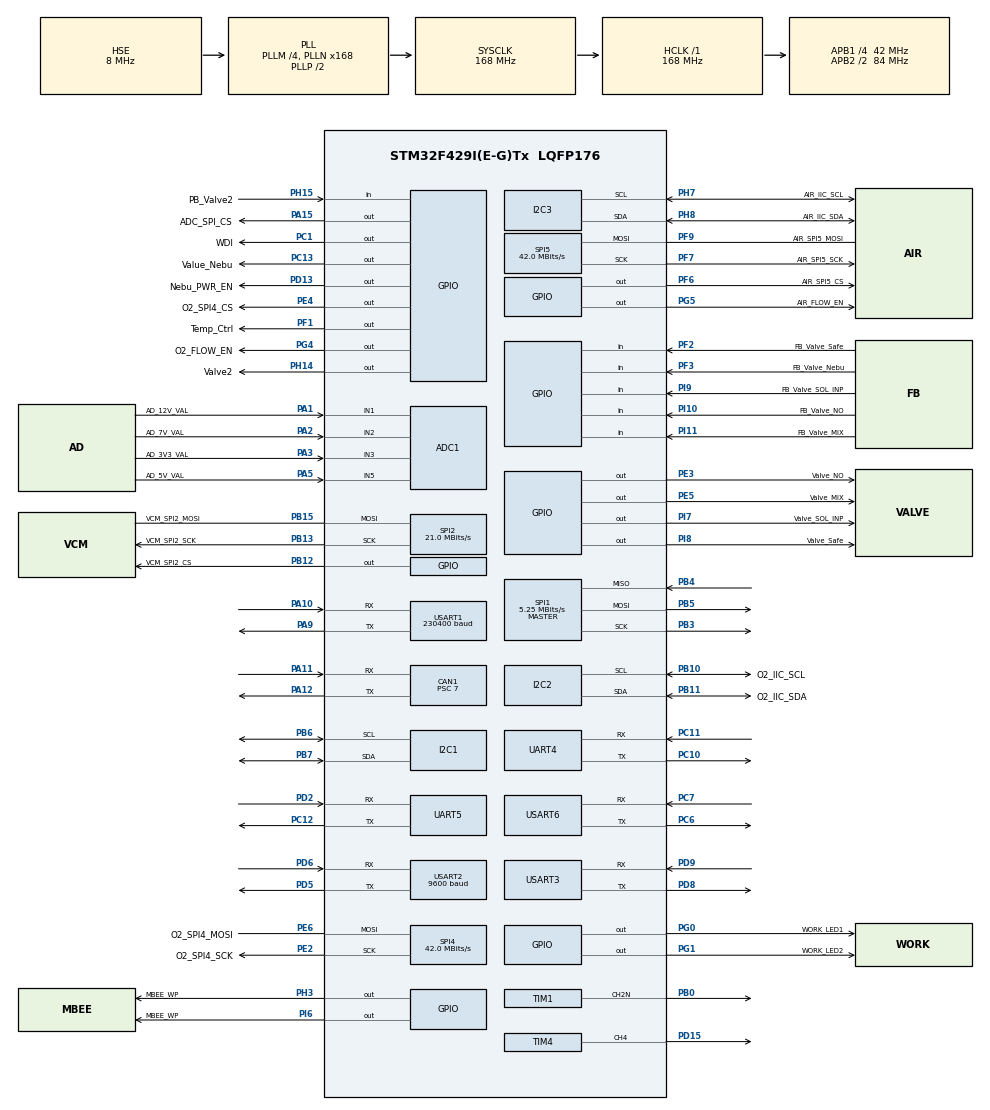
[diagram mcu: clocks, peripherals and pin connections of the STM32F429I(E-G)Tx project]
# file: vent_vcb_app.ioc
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ADC1.Channel-1\#ChannelRegularConversion=ADC_CHANNEL_2
ADC1.Channel-2\#ChannelInjectedConversion=ADC_CHANNEL_1
ADC1.Channel-3\#ChannelInjectedConversion=ADC_CHANNEL_1
ADC1.Channel-4\#ChannelInjectedConversion=ADC_CHANNEL_1
ADC1.Channel-5\#ChannelInjectedConversion=ADC_CHANNEL_1
ADC1.InjNumberOfConversion=4
ADC1.InjectedOffset-2\#ChannelInjectedConversion=0
ADC1.InjectedOffset-3\#ChannelInjectedConversion=0
ADC1.InjectedOffset-4\#ChannelInjectedConversion=0
ADC1.InjectedOffset-5\#ChannelInjectedConversion=0
ADC1.InjectedRank-2\#ChannelInjectedConversion=1
ADC1.InjectedRank-3\#ChannelInjectedConversion=2
ADC1.InjectedRank-4\#ChannelInjectedConversion=3
ADC1.InjectedRank-5\#ChannelInjectedConversion=4
ADC1.NbrOfConversionFlag=1
ADC1.Rank-1\#ChannelRegularConversion=1
ADC1.SamplingTime-1\#ChannelRegularConversion=ADC_SAMPLETIME_3CYCLES
ADC1.SamplingTime-2\#ChannelInjectedConversion=ADC_SAMPLETIME_3CYCLES
ADC1.SamplingTime-3\#ChannelInjectedConversion=ADC_SAMPLETIME_3CYCLES
ADC1.SamplingTime-4\#ChannelInjectedConversion=ADC_SAMPLETIME_3CYCLES
ADC1.SamplingTime-5\#ChannelInjectedConversion=ADC_SAMPLETIME_3CYCLES
ADC1.master=1
CAN1.BS1=CAN_BS1_6TQ
CAN1.BS2=CAN_BS2_5TQ
CAN1.CalculateBaudRate=499999
CAN1.CalculateTimeBit=2000
CAN1.CalculateTimeQuantum=166.66666666666669
CAN1.Mode=CAN_MODE_NORMAL
CAN1.Prescaler=7
FREERTOS.Tasks01=startupTask,24,128,startup_entry,Default,NULL,Static,defaultTaskBuffer,defaultTaskControlBlock
FREERTOS.configUSE_NEWLIB_REENTRANT=1
I2C1.I2C_Mode=I2C_Fast
I2C2.I2C_Mode=I2C_Fast
I2C3.I2C_Mode=I2C_Fast
Mcu.Family=STM32F4
Mcu.Name=STM32F429I(E-G)Tx
Mcu.Package=LQFP176
NVIC.ADC_IRQn=true\:5\:0\:false\:false\:true\:true\:true\:true\:true
NVIC.PriorityGroup=NVIC_PRIORITYGROUP_4
NVIC.TIM6_DAC_IRQn=true\:15\:0\:false\:false\:true\:false\:false\:true\:true
NVIC.TimeBase=TIM6_DAC_IRQn
NVIC.TimeBaseIP=TIM6
NVIC.UART5_IRQn=true\:5\:0\:false\:false\:true\:true\:true\:true\:true
NVIC.USART1_IRQn=true\:5\:0\:false\:false\:true\:true\:true\:true\:true
NVIC.USART2_IRQn=true\:5\:0\:false\:false\:true\:true\:true\:true\:true
NVIC.USART3_IRQn=true\:5\:0\:false\:false\:true\:true\:true\:true\:true
NVIC.USART6_IRQn=true\:5\:0\:false\:false\:true\:true\:true\:true\:true
PA1.GPIO_Label=AD_12V_VAL
PA1.Signal=ADCx_IN1
PA10.Mode=Asynchronous
PA10.Signal=USART1_RX
PA11.GPIO_PuPd=GPIO_PULLUP
PA11.Mode=CAN_Activate
PA11.Signal=CAN1_RX
PA12.Mode=CAN_Activate
PA12.Signal=CAN1_TX
PA13.Mode=Serial_Wire
PA13.Signal=SYS_JTMS-SWDIO
PA14.Mode=Serial_Wire
PA14.Signal=SYS_JTCK-SWCLK
PA15.GPIO_Label=ADC_SPI_CS
PA15.Signal=GPIO_Output
PA2.GPIO_Label=AD_7V_VAL
PA2.Signal=ADCx_IN2
PA3.GPIO_Label=AD_3V3_VAL
PA3.Signal=ADCx_IN3
PA5.GPIO_Label=AD_5V_VAL
PA5.Signal=ADCx_IN5
PA6.GPIO_Label=ADC_3V3_VAL
PA6.Signal=ADCx_IN6
PA7.GPIO_Label=ADC_5V_VAL
PA7.Signal=ADCx_IN7
PA9.Mode=Asynchronous
PA9.Signal=USART1_TX
PB0.Mode=Output Compare2 CH2N
PB0.Signal=TIM1_CH2N
PB10.GPIO_Label=O2_IIC_SCL
PB10.Mode=I2C
PB10.Signal=I2C2_SCL
PB11.GPIO_Label=O2_IIC_SDA
PB11.Mode=I2C
PB11.Signal=I2C2_SDA
PB12.GPIO_Label=VCM_SPI2_CS
PB12.Signal=GPIO_Output
PB13.GPIO_Label=VCM_SPI2_SCK
PB13.Mode=Simplex_Bidirectional_Master
PB13.Signal=SPI2_SCK
PB15.GPIO_Label=VCM_SPI2_MOSI
PB15.Mode=Simplex_Bidirectional_Master
PB15.Signal=SPI2_MOSI
PB3.Mode=Full_Duplex_Master
PB3.Signal=SPI1_SCK
PB4.Mode=Full_Duplex_Master
PB4.Signal=SPI1_MISO
PB5.Mode=Full_Duplex_Master
PB5.Signal=SPI1_MOSI
PB6.Mode=I2C
PB6.Signal=I2C1_SCL
PB7.Mode=I2C
PB7.Signal=I2C1_SDA
PC1.GPIO_Label=WDI
PC1.Signal=GPIO_Output
PC10.Mode=Asynchronous
PC10.Signal=UART4_TX
PC11.Mode=Asynchronous
PC11.Signal=UART4_RX
PC12.Mode=Asynchronous
PC12.Signal=UART5_TX
PC13.GPIO_Label=Value_Nebu
PC13.Signal=GPIO_Output
PC6.Mode=Asynchronous
PC6.Signal=USART6_TX
PC7.Mode=Asynchronous
PC7.Signal=USART6_RX
PD13.GPIO_Label=Nebu_PWR_EN
PD13.Signal=GPIO_Output
PD15.Signal=S_TIM4_CH4
PD2.Mode=Asynchronous
PD2.Signal=UART5_RX
PD5.Mode=Asynchronous
PD5.Signal=USART2_TX
PD6.Mode=Asynchronous
PD6.Signal=USART2_RX
PD8.Mode=Asynchronous
PD8.Signal=USART3_TX
PD9.Mode=Asynchronous
PD9.Signal=USART3_RX
PE2.GPIO_Label=O2_SPI4_SCK
PE2.Mode=Simplex_Bidirectional_Master
PE2.Signal=SPI4_SCK
PE3.GPIO_Label=Valve_NO
PE3.Signal=GPIO_Output
PE4.GPIO_Label=O2_SPI4_CS
PE4.Signal=GPIO_Output
PE5.GPIO_Label=Valve_MIX
PE5.Signal=GPIO_Output
PE6.GPIO_Label=O2_SPI4_MOSI
PE6.Mode=Simplex_Bidirectional_Master
PE6.Signal=SPI4_MOSI
PF1.GPIO_Label=Temp_Ctrl
PF1.Signal=GPIO_Output
PF2.GPIO_Label=FB_Valve_Safe
PF2.Signal=GPIO_Input
PF3.GPIO_Label=FB_Valve_Nebu
PF3.Signal=GPIO_Input
PF6.GPIO_Label=AIR_SPI5_CS
PF6.Signal=GPIO_Output
PF7.GPIO_Label=AIR_SPI5_SCK
PF7.Mode=Simplex_Bidirectional_Master
PF7.Signal=SPI5_SCK
PF9.GPIO_Label=AIR_SPI5_MOSI
PF9.Mode=Simplex_Bidirectional_Master
PF9.Signal=SPI5_MOSI
PG0.GPIO_Label=WORK_LED1
PG0.Signal=GPIO_Output
PG1.GPIO_Label=WORK_LED2
PG1.Signal=GPIO_Output
PG4.GPIO_Label=O2_FLOW_EN
PG4.Signal=GPIO_Output
PG5.GPIO_Label=AIR_FLOW_EN
PG5.Signal=GPIO_Output
PH0/OSC_IN.Mode=HSE-External-Oscillator
PH0/OSC_IN.Signal=RCC_OSC_IN
PH1/OSC_OUT.Mode=HSE-External-Oscillator
PH1/OSC_OUT.Signal=RCC_OSC_OUT
PH14.GPIO_Label=Valve2
PH14.Signal=GPIO_Output
PH15.GPIO_Label=PB_Valve2
PH15.Signal=GPIO_Input
PH3.GPIO_Label=MBEE_WP
PH3.Signal=GPIO_Output
PH7.GPIO_Label=AIR_IIC_SCL
PH7.Mode=I2C
PH7.Signal=I2C3_SCL
PH8.GPIO_Label=AIR_IIC_SDA
PH8.Mode=I2C
PH8.Signal=I2C3_SDA
PI10.GPIO_Label=FB_Valve_NO
PI10.Signal=GPIO_Input
PI11.GPIO_Label=FB_Valve_MIX
PI11.Signal=GPIO_Input
PI6.GPIO_Label=MBEE_WP
PI6.Signal=GPIO_Output
PI7.GPIO_Label=Valve_SOL_INP
PI7.PinState=GPIO_PIN_SET
PI7.Signal=GPIO_Output
PI8.GPIO_Label=Valve_Safe
PI8.Signal=GPIO_Output
PI9.GPIO_Label=FB_Valve_SOL_INP
PI9.Signal=GPIO_Input
ProjectManager.HeapSize=0x200
ProjectManager.StackSize=0x400
ProjectManager.TargetToolchain=STM32CubeIDE
RCC.48MHZClocksFreq_Value=84000000
RCC.AHBFreq_Value=168000000
RCC.APB1CLKDivider=RCC_HCLK_DIV4
RCC.APB1Freq_Value=42000000
RCC.APB1TimFreq_Value=84000000
RCC.APB2CLKDivider=RCC_HCLK_DIV2
RCC.APB2Freq_Value=84000000
RCC.APB2TimFreq_Value=168000000
RCC.CortexFreq_Value=168000000
RCC.HCLKFreq_Value=168000000
RCC.HSE_VALUE=8000000
RCC.HSI_VALUE=16000000
RCC.LSE_VALUE=32768
RCC.PLLM=4
RCC.PLLN=168
RCC.PLLSourceVirtual=RCC_PLLSOURCE_HSE
RCC.SYSCLKFreq_VALUE=168000000
RCC.SYSCLKSource=RCC_SYSCLKSOURCE_PLLCLK
RCC.VCOOutputFreq_Value=336000000
SH.ADCx_IN1.0=ADC1_IN1,IN1
SH.ADCx_IN2.0=ADC1_IN2,IN2
SH.ADCx_IN3.0=ADC1_IN3,IN3
SH.ADCx_IN5.0=ADC1_IN5,IN5
SH.ADCx_IN6.0=ADC1_IN6
SH.ADCx_IN7.0=ADC1_IN7
SH.S_TIM4_CH4.0=TIM4_CH4,PWM Generation4 CH4
SPI1.BaudRatePrescaler=SPI_BAUDRATEPRESCALER_16
SPI1.CLKPhase=SPI_PHASE_1EDGE
SPI1.CalculateBaudRate=5.25 MBits/s
SPI1.DataSize=SPI_DATASIZE_8BIT
SPI1.Direction=SPI_DIRECTION_2LINES
SPI1.Mode=SPI_MODE_MASTER
SPI1.VirtualType=VM_MASTER
SPI2.CLKPhase=SPI_PHASE_2EDGE
SPI2.CalculateBaudRate=21.0 MBits/s
SPI2.Direction=SPI_DIRECTION_1LINE
SPI2.FirstBit=SPI_FIRSTBIT_MSB
SPI2.Mode=SPI_MODE_MASTER
SPI2.VirtualType=VM_MASTER
SPI4.CLKPhase=SPI_PHASE_2EDGE
SPI4.CalculateBaudRate=42.0 MBits/s
SPI4.DataSize=SPI_DATASIZE_8BIT
SPI4.Direction=SPI_DIRECTION_1LINE
SPI4.FirstBit=SPI_FIRSTBIT_MSB
SPI4.Mode=SPI_MODE_MASTER
SPI4.VirtualType=VM_MASTER
SPI5.BaudRatePrescaler=SPI_BAUDRATEPRESCALER_2
SPI5.CLKPhase=SPI_PHASE_2EDGE
SPI5.CalculateBaudRate=42.0 MBits/s
SPI5.Direction=SPI_DIRECTION_1LINE
SPI5.FirstBit=SPI_FIRSTBIT_MSB
SPI5.Mode=SPI_MODE_MASTER
SPI5.VirtualType=VM_MASTER
TIM1.Channel-Output\ Compare2\ CH2N=TIM_CHANNEL_2
TIM1.Period=1000-1
TIM1.Prescaler=64-1
TIM4.Channel-PWM\ Generation4\ CH4=TIM_CHANNEL_4
TIM4.Period=1000-1
TIM4.Prescaler=64-1
UART4.VirtualMode=Asynchronous
UART5.VirtualMode=Asynchronous
USART1.BaudRate=230400
USART1.VirtualMode=VM_ASYNC
USART2.BaudRate=9600
USART2.VirtualMode=VM_ASYNC
USART3.VirtualMode=VM_ASYNC
USART6.VirtualMode=VM_ASYNC
VP_FREERTOS_VS_CMSIS_V2.Mode=CMSIS_V2
VP_SYS_VS_tim6.Mode=TIM6
VP_TIM3_VS_ClockSourceITR.Mode=TriggerSource_ITR0
VP_TIM3_VS_ControllerModeClock.Mode=Clock Mode
VP_TIM4_VS_ClockSourceINT.Mode=Internal
board=custom

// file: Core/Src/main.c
/* USER CODE BEGIN Header */
/**
  ******************************************************************************
  * @file           : main.c
  * @brief          : Main program body
  ******************************************************************************
  * @attention
  *
  * Copyright (c) 2024 STMicroelectronics.
  * All rights reserved.
  *
  * This software is licensed under terms that can be found in the LICENSE file
  * in the root directory of this software component.
  * If no LICENSE file comes with this software, it is provided AS-IS.
  *
  ******************************************************************************
  */
/* USER CODE END Header */
#include "main.h"
#include "cmsis_os.h"

/* USER CODE BEGIN Includes */
#include "../system/startup/vent_startup.h"
/* USER CODE END Includes */

typedef StaticTask_t osStaticThreadDef_t;

ADC_HandleTypeDef hadc1;

CAN_HandleTypeDef hcan1;

I2C_HandleTypeDef hi2c1;
I2C_HandleTypeDef hi2c2;
I2C_HandleTypeDef hi2c3;

SPI_HandleTypeDef hspi1;
SPI_HandleTypeDef hspi2;
SPI_HandleTypeDef hspi4;
SPI_HandleTypeDef hspi5;

TIM_HandleTypeDef htim1;
TIM_HandleTypeDef htim3;
TIM_HandleTypeDef htim4;

UART_HandleTypeDef huart4;
UART_HandleTypeDef huart5;
UART_HandleTypeDef huart1;
UART_HandleTypeDef huart2;
UART_HandleTypeDef huart3;
UART_HandleTypeDef huart6;

/* Definitions for startupTask */
osThreadId_t startupTaskHandle;
uint32_t defaultTaskBuffer[ 128 ];
osStaticThreadDef_t defaultTaskControlBlock;
const osThreadAttr_t startupTask_attributes = {
  .name = "startupTask",
  .cb_mem = &defaultTaskControlBlock,
  .cb_size = sizeof(defaultTaskControlBlock),
  .stack_mem = &defaultTaskBuffer[0],
  .stack_size = sizeof(defaultTaskBuffer),
  .priority = (osPriority_t) osPriorityNormal,
};

void SystemClock_Config(void);
static void MX_GPIO_Init(void);
static void MX_USART1_UART_Init(void);
static void MX_CAN1_Init(void);
static void MX_ADC1_Init(void);
static void MX_SPI1_Init(void);
static void MX_SPI2_Init(void);
static void MX_I2C2_Init(void);
static void MX_I2C3_Init(void);
static void MX_SPI4_Init(void);
static void MX_SPI5_Init(void);
static void MX_UART4_Init(void);
static void MX_UART5_Init(void);
static void MX_USART2_UART_Init(void);
static void MX_USART3_UART_Init(void);
static void MX_USART6_UART_Init(void);
static void MX_TIM3_Init(void);
static void MX_TIM4_Init(void);
static void MX_TIM1_Init(void);
static void MX_I2C1_Init(void);
void startup_entry(void *argument);

int main(void)
{

  /* MCU Configuration--------------------------------------------------------*/

  /* Reset of all peripherals, Initializes the Flash interface and the Systick. */
  HAL_Init();

  /* Configure the system clock */
  SystemClock_Config();

  /* Initialize all configured peripherals */
  MX_GPIO_Init();
  MX_USART1_UART_Init();
  MX_CAN1_Init();
  MX_ADC1_Init();
  MX_SPI1_Init();
  MX_SPI2_Init();
  MX_I2C2_Init();
  MX_I2C3_Init();
  MX_SPI4_Init();
  MX_SPI5_Init();
  MX_UART4_Init();
  MX_UART5_Init();
  MX_USART2_UART_Init();
  MX_USART3_UART_Init();
  MX_USART6_UART_Init();
  MX_TIM3_Init();
  MX_TIM4_Init();
  MX_TIM1_Init();
  MX_I2C1_Init();

  /* Init scheduler */
  osKernelInitialize();

  /* Create the thread(s) */
  /* creation of startupTask */
  startupTaskHandle = osThreadNew(startup_entry, NULL, &startupTask_attributes);

  /* Start scheduler */
  osKernelStart();

  /* We should never get here as control is now taken by the scheduler */
  /* Infinite loop */
  while (1)
  {

  }
}

void SystemClock_Config(void)
{
  RCC_OscInitTypeDef RCC_OscInitStruct = {0};
  RCC_ClkInitTypeDef RCC_ClkInitStruct = {0};

  /** Configure the main internal regulator output voltage
  */
  __HAL_RCC_PWR_CLK_ENABLE();
  __HAL_PWR_VOLTAGESCALING_CONFIG(PWR_REGULATOR_VOLTAGE_SCALE1);

  /** Initializes the RCC Oscillators according to the specified parameters
  * in the RCC_OscInitTypeDef structure.
  */
  RCC_OscInitStruct.OscillatorType = RCC_OSCILLATORTYPE_HSE;
  RCC_OscInitStruct.HSEState = RCC_HSE_ON;
  RCC_OscInitStruct.PLL.PLLState = RCC_PLL_ON;
  RCC_OscInitStruct.PLL.PLLSource = RCC_PLLSOURCE_HSE;
  RCC_OscInitStruct.PLL.PLLM = 4;
  RCC_OscInitStruct.PLL.PLLN = 168;
  RCC_OscInitStruct.PLL.PLLP = RCC_PLLP_DIV2;
  RCC_OscInitStruct.PLL.PLLQ = 4;
  if (HAL_RCC_OscConfig(&RCC_OscInitStruct) != HAL_OK)
  {
    Error_Handler();
  }

  /** Initializes the CPU, AHB and APB buses clocks
  */
  RCC_ClkInitStruct.ClockType = RCC_CLOCKTYPE_HCLK|RCC_CLOCKTYPE_SYSCLK
                              |RCC_CLOCKTYPE_PCLK1|RCC_CLOCKTYPE_PCLK2;
  RCC_ClkInitStruct.SYSCLKSource = RCC_SYSCLKSOURCE_PLLCLK;
  RCC_ClkInitStruct.AHBCLKDivider = RCC_SYSCLK_DIV1;
  RCC_ClkInitStruct.APB1CLKDivider = RCC_HCLK_DIV4;
  RCC_ClkInitStruct.APB2CLKDivider = RCC_HCLK_DIV2;

  if (HAL_RCC_ClockConfig(&RCC_ClkInitStruct, FLASH_LATENCY_5) != HAL_OK)
  {
    Error_Handler();
  }
}

static void MX_ADC1_Init(void)
{

  ADC_ChannelConfTypeDef sConfig = {0};
  ADC_InjectionConfTypeDef sConfigInjected = {0};

  /** Configure the global features of the ADC (Clock, Resolution, Data Alignment and number of conversion)
  */
  hadc1.Instance = ADC1;
  hadc1.Init.ClockPrescaler = ADC_CLOCK_SYNC_PCLK_DIV4;
  hadc1.Init.Resolution = ADC_RESOLUTION_12B;
  hadc1.Init.ScanConvMode = ENABLE;
  hadc1.Init.ContinuousConvMode = DISABLE;
  hadc1.Init.DiscontinuousConvMode = DISABLE;
  hadc1.Init.ExternalTrigConvEdge = ADC_EXTERNALTRIGCONVEDGE_NONE;
  hadc1.Init.ExternalTrigConv = ADC_SOFTWARE_START;
  hadc1.Init.DataAlign = ADC_DATAALIGN_RIGHT;
  hadc1.Init.NbrOfConversion = 1;
  hadc1.Init.DMAContinuousRequests = DISABLE;
  hadc1.Init.EOCSelection = ADC_EOC_SINGLE_CONV;
  if (HAL_ADC_Init(&hadc1) != HAL_OK)
  {
    Error_Handler();
  }

  /** Configure for the selected ADC regular channel its corresponding rank in the sequencer and its sample time.
  */
  sConfig.Channel = ADC_CHANNEL_2;
  sConfig.Rank = 1;
  sConfig.SamplingTime = ADC_SAMPLETIME_3CYCLES;
  if (HAL_ADC_ConfigChannel(&hadc1, &sConfig) != HAL_OK)
  {
    Error_Handler();
  }

  /** Configures for the selected ADC injected channel its corresponding rank in the sequencer and its sample time
  */
  sConfigInjected.InjectedChannel = ADC_CHANNEL_1;
  sConfigInjected.InjectedRank = 1;
  sConfigInjected.InjectedNbrOfConversion = 4;
  sConfigInjected.InjectedSamplingTime = ADC_SAMPLETIME_3CYCLES;
  sConfigInjected.ExternalTrigInjecConvEdge = ADC_EXTERNALTRIGINJECCONVEDGE_NONE;
  sConfigInjected.ExternalTrigInjecConv = ADC_INJECTED_SOFTWARE_START;
  sConfigInjected.AutoInjectedConv = DISABLE;
  sConfigInjected.InjectedDiscontinuousConvMode = DISABLE;
  sConfigInjected.InjectedOffset = 0;
  if (HAL_ADCEx_InjectedConfigChannel(&hadc1, &sConfigInjected) != HAL_OK)
  {
    Error_Handler();
  }

  /** Configures for the selected ADC injected channel its corresponding rank in the sequencer and its sample time
  */
  sConfigInjected.InjectedRank = 2;
  if (HAL_ADCEx_InjectedConfigChannel(&hadc1, &sConfigInjected) != HAL_OK)
  {
    Error_Handler();
  }

  /** Configures for the selected ADC injected channel its corresponding rank in the sequencer and its sample time
  */
  sConfigInjected.InjectedRank = 3;
  if (HAL_ADCEx_InjectedConfigChannel(&hadc1, &sConfigInjected) != HAL_OK)
  {
    Error_Handler();
  }

  /** Configures for the selected ADC injected channel its corresponding rank in the sequencer and its sample time
  */
  sConfigInjected.InjectedRank = 4;
  if (HAL_ADCEx_InjectedConfigChannel(&hadc1, &sConfigInjected) != HAL_OK)
  {
    Error_Handler();
  }

}

static void MX_CAN1_Init(void)
{

  hcan1.Instance = CAN1;
  hcan1.Init.Prescaler = 7;
  hcan1.Init.Mode = CAN_MODE_NORMAL;
  hcan1.Init.SyncJumpWidth = CAN_SJW_1TQ;
  hcan1.Init.TimeSeg1 = CAN_BS1_6TQ;
  hcan1.Init.TimeSeg2 = CAN_BS2_5TQ;
  hcan1.Init.TimeTriggeredMode = DISABLE;
  hcan1.Init.AutoBusOff = DISABLE;
  hcan1.Init.AutoWakeUp = DISABLE;
  hcan1.Init.AutoRetransmission = DISABLE;
  hcan1.Init.ReceiveFifoLocked = DISABLE;
  hcan1.Init.TransmitFifoPriority = DISABLE;
  if (HAL_CAN_Init(&hcan1) != HAL_OK)
  {
    Error_Handler();
  }

}

static void MX_I2C1_Init(void)
{

  hi2c1.Instance = I2C1;
  hi2c1.Init.ClockSpeed = 100000;
  hi2c1.Init.DutyCycle = I2C_DUTYCYCLE_2;
  hi2c1.Init.OwnAddress1 = 0;
  hi2c1.Init.AddressingMode = I2C_ADDRESSINGMODE_7BIT;
  hi2c1.Init.DualAddressMode = I2C_DUALADDRESS_DISABLE;
  hi2c1.Init.OwnAddress2 = 0;
  hi2c1.Init.GeneralCallMode = I2C_GENERALCALL_DISABLE;
  hi2c1.Init.NoStretchMode = I2C_NOSTRETCH_DISABLE;
  if (HAL_I2C_Init(&hi2c1) != HAL_OK)
  {
    Error_Handler();
  }

  /** Configure Analogue filter
  */
  if (HAL_I2CEx_ConfigAnalogFilter(&hi2c1, I2C_ANALOGFILTER_ENABLE) != HAL_OK)
  {
    Error_Handler();
  }

  /** Configure Digital filter
  */
  if (HAL_I2CEx_ConfigDigitalFilter(&hi2c1, 0) != HAL_OK)
  {
    Error_Handler();
  }

}

static void MX_I2C2_Init(void)
{

  hi2c2.Instance = I2C2;
  hi2c2.Init.ClockSpeed = 400000;
  hi2c2.Init.DutyCycle = I2C_DUTYCYCLE_2;
  hi2c2.Init.OwnAddress1 = 0;
  hi2c2.Init.AddressingMode = I2C_ADDRESSINGMODE_7BIT;
  hi2c2.Init.DualAddressMode = I2C_DUALADDRESS_DISABLE;
  hi2c2.Init.OwnAddress2 = 0;
  hi2c2.Init.GeneralCallMode = I2C_GENERALCALL_DISABLE;
  hi2c2.Init.NoStretchMode = I2C_NOSTRETCH_DISABLE;
  if (HAL_I2C_Init(&hi2c2) != HAL_OK)
  {
    Error_Handler();
  }

  /** Configure Analogue filter
  */
  if (HAL_I2CEx_ConfigAnalogFilter(&hi2c2, I2C_ANALOGFILTER_ENABLE) != HAL_OK)
  {
    Error_Handler();
  }

  /** Configure Digital filter
  */
  if (HAL_I2CEx_ConfigDigitalFilter(&hi2c2, 0) != HAL_OK)
  {
    Error_Handler();
  }

}

static void MX_I2C3_Init(void)
{

  hi2c3.Instance = I2C3;
  hi2c3.Init.ClockSpeed = 400000;
  hi2c3.Init.DutyCycle = I2C_DUTYCYCLE_2;
  hi2c3.Init.OwnAddress1 = 0;
  hi2c3.Init.AddressingMode = I2C_ADDRESSINGMODE_7BIT;
  hi2c3.Init.DualAddressMode = I2C_DUALADDRESS_DISABLE;
  hi2c3.Init.OwnAddress2 = 0;
  hi2c3.Init.GeneralCallMode = I2C_GENERALCALL_DISABLE;
  hi2c3.Init.NoStretchMode = I2C_NOSTRETCH_DISABLE;
  if (HAL_I2C_Init(&hi2c3) != HAL_OK)
  {
    Error_Handler();
  }

  /** Configure Analogue filter
  */
  if (HAL_I2CEx_ConfigAnalogFilter(&hi2c3, I2C_ANALOGFILTER_ENABLE) != HAL_OK)
  {
    Error_Handler();
  }

  /** Configure Digital filter
  */
  if (HAL_I2CEx_ConfigDigitalFilter(&hi2c3, 0) != HAL_OK)
  {
    Error_Handler();
  }

}

static void MX_SPI1_Init(void)
{

  /* SPI1 parameter configuration*/
  hspi1.Instance = SPI1;
  hspi1.Init.Mode = SPI_MODE_MASTER;
  hspi1.Init.Direction = SPI_DIRECTION_2LINES;
  hspi1.Init.DataSize = SPI_DATASIZE_8BIT;
  hspi1.Init.CLKPolarity = SPI_POLARITY_LOW;
  hspi1.Init.CLKPhase = SPI_PHASE_1EDGE;
  hspi1.Init.NSS = SPI_NSS_SOFT;
  hspi1.Init.BaudRatePrescaler = SPI_BAUDRATEPRESCALER_16;
  hspi1.Init.FirstBit = SPI_FIRSTBIT_MSB;
  hspi1.Init.TIMode = SPI_TIMODE_DISABLE;
  hspi1.Init.CRCCalculation = SPI_CRCCALCULATION_DISABLE;
  hspi1.Init.CRCPolynomial = 10;
  if (HAL_SPI_Init(&hspi1) != HAL_OK)
  {
    Error_Handler();
  }

}

static void MX_SPI2_Init(void)
{

  /* SPI2 parameter configuration*/
  hspi2.Instance = SPI2;
  hspi2.Init.Mode = SPI_MODE_MASTER;
  hspi2.Init.Direction = SPI_DIRECTION_1LINE;
  hspi2.Init.DataSize = SPI_DATASIZE_8BIT;
  hspi2.Init.CLKPolarity = SPI_POLARITY_LOW;
  hspi2.Init.CLKPhase = SPI_PHASE_2EDGE;
  hspi2.Init.NSS = SPI_NSS_SOFT;
  hspi2.Init.BaudRatePrescaler = SPI_BAUDRATEPRESCALER_2;
  hspi2.Init.FirstBit = SPI_FIRSTBIT_MSB;
  hspi2.Init.TIMode = SPI_TIMODE_DISABLE;
  hspi2.Init.CRCCalculation = SPI_CRCCALCULATION_DISABLE;
  hspi2.Init.CRCPolynomial = 10;
  if (HAL_SPI_Init(&hspi2) != HAL_OK)
  {
    Error_Handler();
  }

}

static void MX_SPI4_Init(void)
{

  /* SPI4 parameter configuration*/
  hspi4.Instance = SPI4;
  hspi4.Init.Mode = SPI_MODE_MASTER;
  hspi4.Init.Direction = SPI_DIRECTION_1LINE;
  hspi4.Init.DataSize = SPI_DATASIZE_8BIT;
  hspi4.Init.CLKPolarity = SPI_POLARITY_LOW;
  hspi4.Init.CLKPhase = SPI_PHASE_2EDGE;
  hspi4.Init.NSS = SPI_NSS_SOFT;
  hspi4.Init.BaudRatePrescaler = SPI_BAUDRATEPRESCALER_2;
  hspi4.Init.FirstBit = SPI_FIRSTBIT_MSB;
  hspi4.Init.TIMode = SPI_TIMODE_DISABLE;
  hspi4.Init.CRCCalculation = SPI_CRCCALCULATION_DISABLE;
  hspi4.Init.CRCPolynomial = 10;
  if (HAL_SPI_Init(&hspi4) != HAL_OK)
  {
    Error_Handler();
  }

}

static void MX_SPI5_Init(void)
{

  /* SPI5 parameter configuration*/
  hspi5.Instance = SPI5;
  hspi5.Init.Mode = SPI_MODE_MASTER;
  hspi5.Init.Direction = SPI_DIRECTION_1LINE;
  hspi5.Init.DataSize = SPI_DATASIZE_8BIT;
  hspi5.Init.CLKPolarity = SPI_POLARITY_LOW;
  hspi5.Init.CLKPhase = SPI_PHASE_2EDGE;
  hspi5.Init.NSS = SPI_NSS_SOFT;
  hspi5.Init.BaudRatePrescaler = SPI_BAUDRATEPRESCALER_2;
  hspi5.Init.FirstBit = SPI_FIRSTBIT_MSB;
  hspi5.Init.TIMode = SPI_TIMODE_DISABLE;
  hspi5.Init.CRCCalculation = SPI_CRCCALCULATION_DISABLE;
  hspi5.Init.CRCPolynomial = 10;
  if (HAL_SPI_Init(&hspi5) != HAL_OK)
  {
    Error_Handler();
  }

}

static void MX_TIM1_Init(void)
{

  TIM_MasterConfigTypeDef sMasterConfig = {0};
  TIM_OC_InitTypeDef sConfigOC = {0};
  TIM_BreakDeadTimeConfigTypeDef sBreakDeadTimeConfig = {0};

  htim1.Instance = TIM1;
  htim1.Init.Prescaler = 64-1;
  htim1.Init.CounterMode = TIM_COUNTERMODE_UP;
  htim1.Init.Period = 1000-1;
  htim1.Init.ClockDivision = TIM_CLOCKDIVISION_DIV1;
  htim1.Init.RepetitionCounter = 0;
  htim1.Init.AutoReloadPreload = TIM_AUTORELOAD_PRELOAD_DISABLE;
  if (HAL_TIM_OC_Init(&htim1) != HAL_OK)
  {
    Error_Handler();
  }
  sMasterConfig.MasterOutputTrigger = TIM_TRGO_RESET;
  sMasterConfig.MasterSlaveMode = TIM_MASTERSLAVEMODE_DISABLE;
  if (HAL_TIMEx_MasterConfigSynchronization(&htim1, &sMasterConfig) != HAL_OK)
  {
    Error_Handler();
  }
  sConfigOC.OCMode = TIM_OCMODE_TIMING;
  sConfigOC.Pulse = 0;
  sConfigOC.OCPolarity = TIM_OCPOLARITY_HIGH;
  sConfigOC.OCNPolarity = TIM_OCNPOLARITY_HIGH;
  sConfigOC.OCFastMode = TIM_OCFAST_DISABLE;
  sConfigOC.OCIdleState = TIM_OCIDLESTATE_RESET;
  sConfigOC.OCNIdleState = TIM_OCNIDLESTATE_RESET;
  if (HAL_TIM_OC_ConfigChannel(&htim1, &sConfigOC, TIM_CHANNEL_2) != HAL_OK)
  {
    Error_Handler();
  }
  sBreakDeadTimeConfig.OffStateRunMode = TIM_OSSR_DISABLE;
  sBreakDeadTimeConfig.OffStateIDLEMode = TIM_OSSI_DISABLE;
  sBreakDeadTimeConfig.LockLevel = TIM_LOCKLEVEL_OFF;
  sBreakDeadTimeConfig.DeadTime = 0;
  sBreakDeadTimeConfig.BreakState = TIM_BREAK_DISABLE;
  sBreakDeadTimeConfig.BreakPolarity = TIM_BREAKPOLARITY_HIGH;
  sBreakDeadTimeConfig.AutomaticOutput = TIM_AUTOMATICOUTPUT_DISABLE;
  if (HAL_TIMEx_ConfigBreakDeadTime(&htim1, &sBreakDeadTimeConfig) != HAL_OK)
  {
    Error_Handler();
  }
  HAL_TIM_MspPostInit(&htim1);

}

static void MX_TIM3_Init(void)
{

  TIM_SlaveConfigTypeDef sSlaveConfig = {0};
  TIM_MasterConfigTypeDef sMasterConfig = {0};

  htim3.Instance = TIM3;
  htim3.Init.Prescaler = 0;
  htim3.Init.CounterMode = TIM_COUNTERMODE_UP;
  htim3.Init.Period = 65535;
  htim3.Init.ClockDivision = TIM_CLOCKDIVISION_DIV1;
  htim3.Init.AutoReloadPreload = TIM_AUTORELOAD_PRELOAD_DISABLE;
  if (HAL_TIM_Base_Init(&htim3) != HAL_OK)
  {
    Error_Handler();
  }
  sSlaveConfig.SlaveMode = TIM_SLAVEMODE_EXTERNAL1;
  sSlaveConfig.InputTrigger = TIM_TS_ITR0;
  if (HAL_TIM_SlaveConfigSynchro(&htim3, &sSlaveConfig) != HAL_OK)
  {
    Error_Handler();
  }
  sMasterConfig.MasterOutputTrigger = TIM_TRGO_RESET;
  sMasterConfig.MasterSlaveMode = TIM_MASTERSLAVEMODE_DISABLE;
  if (HAL_TIMEx_MasterConfigSynchronization(&htim3, &sMasterConfig) != HAL_OK)
  {
    Error_Handler();
  }

}

static void MX_TIM4_Init(void)
{

  TIM_ClockConfigTypeDef sClockSourceConfig = {0};
  TIM_MasterConfigTypeDef sMasterConfig = {0};
  TIM_OC_InitTypeDef sConfigOC = {0};

  htim4.Instance = TIM4;
  htim4.Init.Prescaler = 64-1;
  htim4.Init.CounterMode = TIM_COUNTERMODE_UP;
  htim4.Init.Period = 1000-1;
  htim4.Init.ClockDivision = TIM_CLOCKDIVISION_DIV1;
  htim4.Init.AutoReloadPreload = TIM_AUTORELOAD_PRELOAD_DISABLE;
  if (HAL_TIM_Base_Init(&htim4) != HAL_OK)
  {
    Error_Handler();
  }
  sClockSourceConfig.ClockSource = TIM_CLOCKSOURCE_INTERNAL;
  if (HAL_TIM_ConfigClockSource(&htim4, &sClockSourceConfig) != HAL_OK)
  {
    Error_Handler();
  }
  if (HAL_TIM_PWM_Init(&htim4) != HAL_OK)
  {
    Error_Handler();
  }
  sMasterConfig.MasterOutputTrigger = TIM_TRGO_RESET;
  sMasterConfig.MasterSlaveMode = TIM_MASTERSLAVEMODE_DISABLE;
  if (HAL_TIMEx_MasterConfigSynchronization(&htim4, &sMasterConfig) != HAL_OK)
  {
    Error_Handler();
  }
  sConfigOC.OCMode = TIM_OCMODE_PWM1;
  sConfigOC.Pulse = 0;
  sConfigOC.OCPolarity = TIM_OCPOLARITY_HIGH;
  sConfigOC.OCFastMode = TIM_OCFAST_DISABLE;
  if (HAL_TIM_PWM_ConfigChannel(&htim4, &sConfigOC, TIM_CHANNEL_4) != HAL_OK)
  {
    Error_Handler();
  }
  HAL_TIM_MspPostInit(&htim4);

}

static void MX_UART4_Init(void)
{

  huart4.Instance = UART4;
  huart4.Init.BaudRate = 115200;
  huart4.Init.WordLength = UART_WORDLENGTH_8B;
  huart4.Init.StopBits = UART_STOPBITS_1;
  huart4.Init.Parity = UART_PARITY_NONE;
  huart4.Init.Mode = UART_MODE_TX_RX;
  huart4.Init.HwFlowCtl = UART_HWCONTROL_NONE;
  huart4.Init.OverSampling = UART_OVERSAMPLING_16;
  if (HAL_UART_Init(&huart4) != HAL_OK)
  {
    Error_Handler();
  }

}

static void MX_UART5_Init(void)
{

  huart5.Instance = UART5;
  huart5.Init.BaudRate = 115200;
  huart5.Init.WordLength = UART_WORDLENGTH_8B;
  huart5.Init.StopBits = UART_STOPBITS_1;
  huart5.Init.Parity = UART_PARITY_NONE;
  huart5.Init.Mode = UART_MODE_TX_RX;
  huart5.Init.HwFlowCtl = UART_HWCONTROL_NONE;
  huart5.Init.OverSampling = UART_OVERSAMPLING_16;
  if (HAL_UART_Init(&huart5) != HAL_OK)
  {
    Error_Handler();
  }

}

static void MX_USART1_UART_Init(void)
{

  huart1.Instance = USART1;
  huart1.Init.BaudRate = 230400;
  huart1.Init.WordLength = UART_WORDLENGTH_8B;
  huart1.Init.StopBits = UART_STOPBITS_1;
  huart1.Init.Parity = UART_PARITY_NONE;
  huart1.Init.Mode = UART_MODE_TX_RX;
  huart1.Init.HwFlowCtl = UART_HWCONTROL_NONE;
  huart1.Init.OverSampling = UART_OVERSAMPLING_16;
  if (HAL_UART_Init(&huart1) != HAL_OK)
  {
    Error_Handler();
  }

}

static void MX_USART2_UART_Init(void)
{

  huart2.Instance = USART2;
  huart2.Init.BaudRate = 9600;
  huart2.Init.WordLength = UART_WORDLENGTH_8B;
  huart2.Init.StopBits = UART_STOPBITS_1;
  huart2.Init.Parity = UART_PARITY_NONE;
  huart2.Init.Mode = UART_MODE_TX_RX;
  huart2.Init.HwFlowCtl = UART_HWCONTROL_NONE;
  huart2.Init.OverSampling = UART_OVERSAMPLING_16;
  if (HAL_UART_Init(&huart2) != HAL_OK)
  {
    Error_Handler();
  }

}

static void MX_USART3_UART_Init(void)
{

  huart3.Instance = USART3;
  huart3.Init.BaudRate = 115200;
  huart3.Init.WordLength = UART_WORDLENGTH_8B;
  huart3.Init.StopBits = UART_STOPBITS_1;
  huart3.Init.Parity = UART_PARITY_NONE;
  huart3.Init.Mode = UART_MODE_TX_RX;
  huart3.Init.HwFlowCtl = UART_HWCONTROL_NONE;
  huart3.Init.OverSampling = UART_OVERSAMPLING_16;
  if (HAL_UART_Init(&huart3) != HAL_OK)
  {
    Error_Handler();
  }

}

static void MX_USART6_UART_Init(void)
{

  huart6.Instance = USART6;
  huart6.Init.BaudRate = 115200;
  huart6.Init.WordLength = UART_WORDLENGTH_8B;
  huart6.Init.StopBits = UART_STOPBITS_1;
  huart6.Init.Parity = UART_PARITY_NONE;
  huart6.Init.Mode = UART_MODE_TX_RX;
  huart6.Init.HwFlowCtl = UART_HWCONTROL_NONE;
  huart6.Init.OverSampling = UART_OVERSAMPLING_16;
  if (HAL_UART_Init(&huart6) != HAL_OK)
  {
    Error_Handler();
  }

}

static void MX_GPIO_Init(void)
{
  GPIO_InitTypeDef GPIO_InitStruct = {0};

  /* GPIO Ports Clock Enable */
  __HAL_RCC_GPIOE_CLK_ENABLE();
  __HAL_RCC_GPIOI_CLK_ENABLE();
  __HAL_RCC_GPIOC_CLK_ENABLE();
  __HAL_RCC_GPIOF_CLK_ENABLE();
  __HAL_RCC_GPIOH_CLK_ENABLE();
  __HAL_RCC_GPIOA_CLK_ENABLE();
  __HAL_RCC_GPIOB_CLK_ENABLE();
  __HAL_RCC_GPIOG_CLK_ENABLE();
  __HAL_RCC_GPIOD_CLK_ENABLE();

  /*Configure GPIO pin Output Level */
  HAL_GPIO_WritePin(GPIOE, Valve_NO_Pin|O2_SPI4_CS_Pin|Valve_MIX_Pin, GPIO_PIN_RESET);

  /*Configure GPIO pin Output Level */
  HAL_GPIO_WritePin(GPIOI, Valve_Safe_Pin|MBEE_WPI6_Pin, GPIO_PIN_RESET);

  /*Configure GPIO pin Output Level */
  HAL_GPIO_WritePin(GPIOC, Value_Nebu_Pin|WDI_Pin, GPIO_PIN_RESET);

  /*Configure GPIO pin Output Level */
  HAL_GPIO_WritePin(GPIOF, Temp_Ctrl_Pin|AIR_SPI5_CS_Pin, GPIO_PIN_RESET);

  /*Configure GPIO pin Output Level */
  HAL_GPIO_WritePin(GPIOH, MBEE_WP_Pin|Valve2_Pin, GPIO_PIN_RESET);

  /*Configure GPIO pin Output Level */
  HAL_GPIO_WritePin(GPIOG, WORK_LED1_Pin|WORK_LED2_Pin|O2_FLOW_EN_Pin|AIR_FLOW_EN_Pin, GPIO_PIN_RESET);

  /*Configure GPIO pin Output Level */
  HAL_GPIO_WritePin(VCM_SPI2_CS_GPIO_Port, VCM_SPI2_CS_Pin, GPIO_PIN_RESET);

  /*Configure GPIO pin Output Level */
  HAL_GPIO_WritePin(Nebu_PWR_EN_GPIO_Port, Nebu_PWR_EN_Pin, GPIO_PIN_RESET);

  /*Configure GPIO pin Output Level */
  HAL_GPIO_WritePin(ADC_SPI_CS_GPIO_Port, ADC_SPI_CS_Pin, GPIO_PIN_RESET);

  /*Configure GPIO pin Output Level */
  HAL_GPIO_WritePin(Valve_SOL_INP_GPIO_Port, Valve_SOL_INP_Pin, GPIO_PIN_SET);

  /*Configure GPIO pins : Valve_NO_Pin O2_SPI4_CS_Pin Valve_MIX_Pin */
  GPIO_InitStruct.Pin = Valve_NO_Pin|O2_SPI4_CS_Pin|Valve_MIX_Pin;
  GPIO_InitStruct.Mode = GPIO_MODE_OUTPUT_PP;
  GPIO_InitStruct.Pull = GPIO_NOPULL;
  GPIO_InitStruct.Speed = GPIO_SPEED_FREQ_LOW;
  HAL_GPIO_Init(GPIOE, &GPIO_InitStruct);

  /*Configure GPIO pins : Valve_Safe_Pin MBEE_WPI6_Pin Valve_SOL_INP_Pin */
  GPIO_InitStruct.Pin = Valve_Safe_Pin|MBEE_WPI6_Pin|Valve_SOL_INP_Pin;
  GPIO_InitStruct.Mode = GPIO_MODE_OUTPUT_PP;
  GPIO_InitStruct.Pull = GPIO_NOPULL;
  GPIO_InitStruct.Speed = GPIO_SPEED_FREQ_LOW;
  HAL_GPIO_Init(GPIOI, &GPIO_InitStruct);

  /*Configure GPIO pins : Value_Nebu_Pin WDI_Pin */
  GPIO_InitStruct.Pin = Value_Nebu_Pin|WDI_Pin;
  GPIO_InitStruct.Mode = GPIO_MODE_OUTPUT_PP;
  GPIO_InitStruct.Pull = GPIO_NOPULL;
  GPIO_InitStruct.Speed = GPIO_SPEED_FREQ_LOW;
  HAL_GPIO_Init(GPIOC, &GPIO_InitStruct);

  /*Configure GPIO pins : FB_Valve_SOL_INP_Pin FB_Valve_NO_Pin FB_Valve_MIX_Pin */
  GPIO_InitStruct.Pin = FB_Valve_SOL_INP_Pin|FB_Valve_NO_Pin|FB_Valve_MIX_Pin;
  GPIO_InitStruct.Mode = GPIO_MODE_INPUT;
  GPIO_InitStruct.Pull = GPIO_NOPULL;
  HAL_GPIO_Init(GPIOI, &GPIO_InitStruct);

  /*Configure GPIO pins : Temp_Ctrl_Pin AIR_SPI5_CS_Pin */
  GPIO_InitStruct.Pin = Temp_Ctrl_Pin|AIR_SPI5_CS_Pin;
  GPIO_InitStruct.Mode = GPIO_MODE_OUTPUT_PP;
  GPIO_InitStruct.Pull = GPIO_NOPULL;
  GPIO_InitStruct.Speed = GPIO_SPEED_FREQ_LOW;
  HAL_GPIO_Init(GPIOF, &GPIO_InitStruct);

  /*Configure GPIO pins : FB_Valve_Safe_Pin FB_Valve_Nebu_Pin */
  GPIO_InitStruct.Pin = FB_Valve_Safe_Pin|FB_Valve_Nebu_Pin;
  GPIO_InitStruct.Mode = GPIO_MODE_INPUT;
  GPIO_InitStruct.Pull = GPIO_NOPULL;
  HAL_GPIO_Init(GPIOF, &GPIO_InitStruct);

  /*Configure GPIO pins : MBEE_WP_Pin Valve2_Pin */
  GPIO_InitStruct.Pin = MBEE_WP_Pin|Valve2_Pin;
  GPIO_InitStruct.Mode = GPIO_MODE_OUTPUT_PP;
  GPIO_InitStruct.Pull = GPIO_NOPULL;
  GPIO_InitStruct.Speed = GPIO_SPEED_FREQ_LOW;
  HAL_GPIO_Init(GPIOH, &GPIO_InitStruct);

  /*Configure GPIO pins : WORK_LED1_Pin WORK_LED2_Pin O2_FLOW_EN_Pin AIR_FLOW_EN_Pin */
  GPIO_InitStruct.Pin = WORK_LED1_Pin|WORK_LED2_Pin|O2_FLOW_EN_Pin|AIR_FLOW_EN_Pin;
  GPIO_InitStruct.Mode = GPIO_MODE_OUTPUT_PP;
  GPIO_InitStruct.Pull = GPIO_NOPULL;
  GPIO_InitStruct.Speed = GPIO_SPEED_FREQ_LOW;
  HAL_GPIO_Init(GPIOG, &GPIO_InitStruct);

  /*Configure GPIO pin : VCM_SPI2_CS_Pin */
  GPIO_InitStruct.Pin = VCM_SPI2_CS_Pin;
  GPIO_InitStruct.Mode = GPIO_MODE_OUTPUT_PP;
  GPIO_InitStruct.Pull = GPIO_NOPULL;
  GPIO_InitStruct.Speed = GPIO_SPEED_FREQ_LOW;
  HAL_GPIO_Init(VCM_SPI2_CS_GPIO_Port, &GPIO_InitStruct);

  /*Configure GPIO pin : Nebu_PWR_EN_Pin */
  GPIO_InitStruct.Pin = Nebu_PWR_EN_Pin;
  GPIO_InitStruct.Mode = GPIO_MODE_OUTPUT_PP;
  GPIO_InitStruct.Pull = GPIO_NOPULL;
  GPIO_InitStruct.Speed = GPIO_SPEED_FREQ_LOW;
  HAL_GPIO_Init(Nebu_PWR_EN_GPIO_Port, &GPIO_InitStruct);

  /*Configure GPIO pin : PB_Valve2_Pin */
  GPIO_InitStruct.Pin = PB_Valve2_Pin;
  GPIO_InitStruct.Mode = GPIO_MODE_INPUT;
  GPIO_InitStruct.Pull = GPIO_NOPULL;
  HAL_GPIO_Init(PB_Valve2_GPIO_Port, &GPIO_InitStruct);

  /*Configure GPIO pin : ADC_SPI_CS_Pin */
  GPIO_InitStruct.Pin = ADC_SPI_CS_Pin;
  GPIO_InitStruct.Mode = GPIO_MODE_OUTPUT_PP;
  GPIO_InitStruct.Pull = GPIO_NOPULL;
  GPIO_InitStruct.Speed = GPIO_SPEED_FREQ_LOW;
  HAL_GPIO_Init(ADC_SPI_CS_GPIO_Port, &GPIO_InitStruct);

}

void startup_entry(void *argument)
{
  /* USER CODE BEGIN 5 */
	vent_startup(argument);
  /* Infinite loop */
  for(;;)
  {
    osDelay(1);
  }
  /* USER CODE END 5 */
}

void HAL_TIM_PeriodElapsedCallback(TIM_HandleTypeDef *htim)
{
  if (htim->Instance == TIM6) {
    HAL_IncTick();
  }
}

void Error_Handler(void)
{
  __disable_irq();
  while (1)
  {
  }
}
